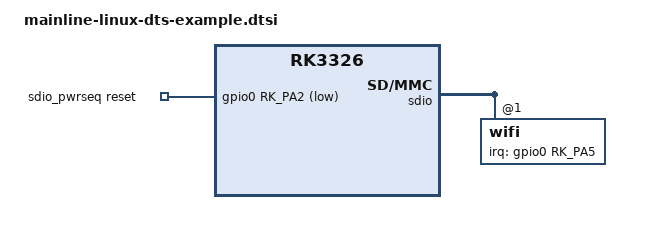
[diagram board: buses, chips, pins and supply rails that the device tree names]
/dts-v1/;

#include <dt-bindings/pinctrl/rockchip.h>
#include "rk3326.dtsi"

/ {
    sdio_pwrseq: sdio-pwrseq {
        compatible = "mmc-pwrseq-simple";
        pinctrl-0 = <&wifi_enable_h>;
        pinctrl-names = "default";
        post-power-on-delay-ms = <100>;
        reset-gpios = <&gpio0 RK_PA2 GPIO_ACTIVE_LOW>;
    };
};

&sdio {
    cap-sd-highspeed;
    cap-sdio-irq;
    mmc-pwrseq = <&sdio_pwrseq>;
    max-frequency = <50000000>;
    no-sd;
    no-mmc;
    supports-rk912;
    status = "okay";

    wifi@1 {
        reg = <1>;
        interrupt-names = "host-wake";
        interrupt-parent = <&gpio0>;
        interrupts = <RK_PA5 IRQ_TYPE_LEVEL_HIGH>;
        pinctrl-0 = <&wifi_host_wake_l>;
        pinctrl-names = "default";
    };
};

&pinctrl {
    wifi {
        wifi_enable_h: wifi-enable-h {
            rockchip,pins = <0 RK_PA2 RK_FUNC_GPIO &pcfg_pull_none>;
        };
        wifi_host_wake_l: wifi-host-wake-l {
            rockchip,pins = <0 RK_PA5 RK_FUNC_GPIO &pcfg_pull_down>;
        };
    };
};
